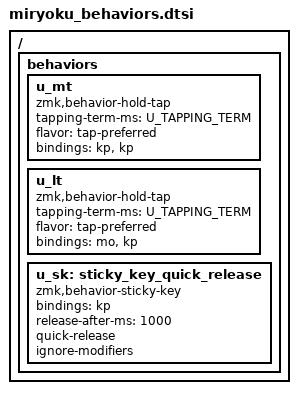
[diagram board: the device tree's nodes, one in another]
// Copyright 2022 Manna Harbour
// https://github.com/manna-harbour/miryoku

/ {
  behaviors {
    u_mt: u_mt {
      compatible = "zmk,behavior-hold-tap";
      #binding-cells = <2>;
      tapping-term-ms = <U_TAPPING_TERM>;
      flavor = "tap-preferred";
      bindings = <&kp>, <&kp>;
    };
    u_lt: u_lt {
      compatible = "zmk,behavior-hold-tap";
      #binding-cells = <2>;
      tapping-term-ms = <U_TAPPING_TERM>;
      flavor = "tap-preferred";
      bindings = <&mo>, <&kp>;
    };
    u_sk: sticky_key_quick_release {
      compatible = "zmk,behavior-sticky-key";
      #binding-cells = <1>;
      bindings = <&kp>;
      release-after-ms = <1000>;
      quick-release;
      ignore-modifiers;
    };
  };
};
